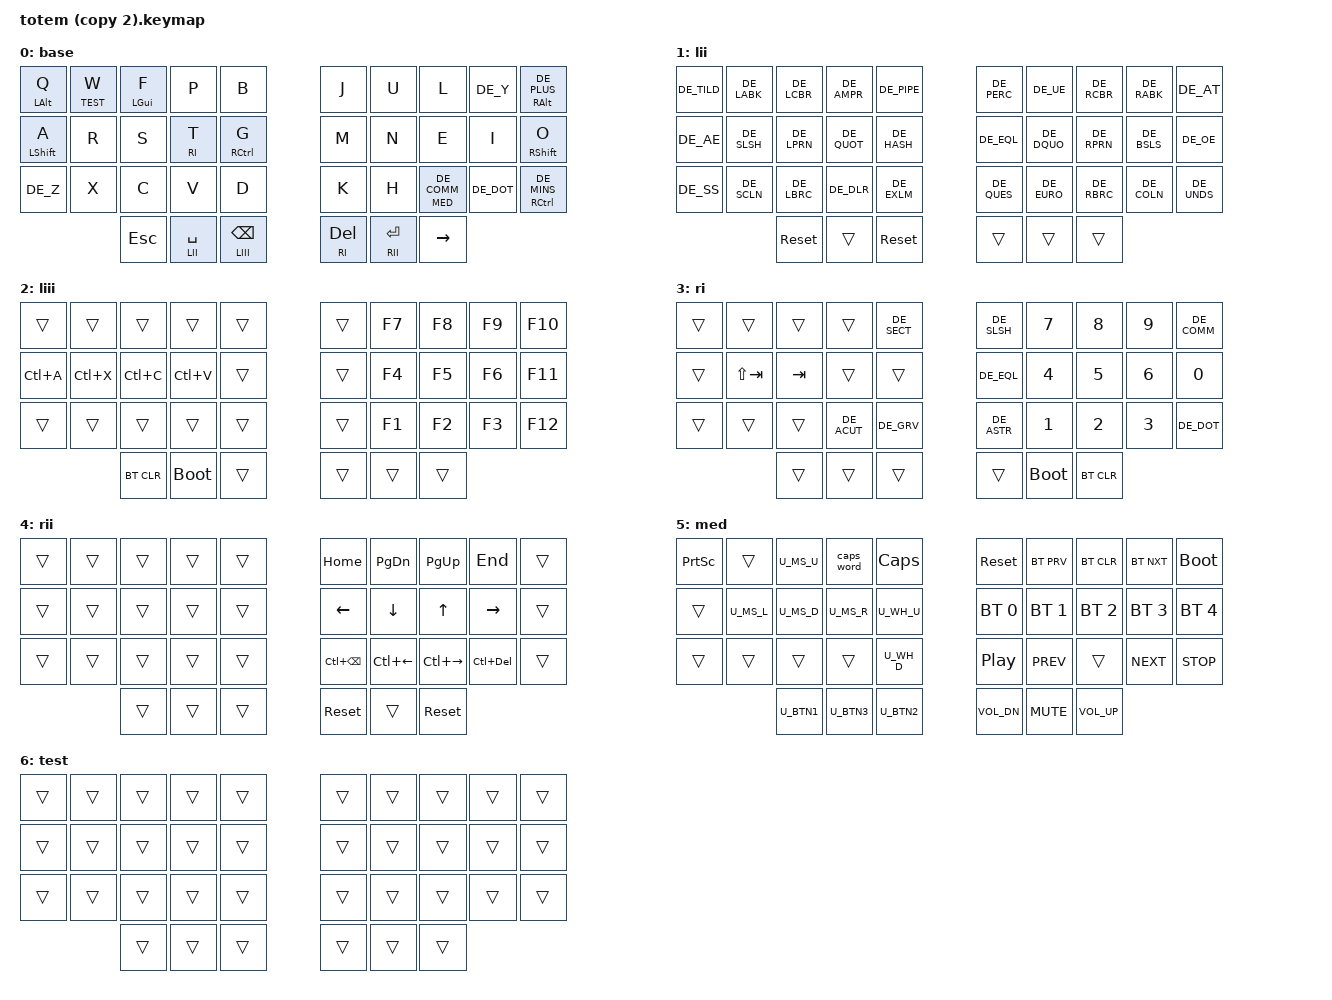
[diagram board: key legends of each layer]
// g f austauschen ... a nachlöten, switch ooooooAAZZAAQQoooAAAISEoooIsFLHAHVE
#include <behaviors.dtsi>
#include <dt-bindings/zmk/keys.h>
#include <dt-bindings/zmk/bt.h>
#include <dt-bindings/zmk/outputs.h>
#include "helper.h"
#define HOST_OS 1
#include "german-keymap.h"
#include "mouse.dtsi"

#define XXX &none
#define ___ &trans

#define BASE 0
#define LII  1
#define LIII 2
#define RI   3
#define RII  4
#define MED  5
#define TEST 6

&mt {
  quick-tap-ms = <175>;
  global-quick-tap;
  flavor = "balanced";
  tapping-term-ms = <200>;
};

// CONFIG_ZMK_SLEEP=y
// CONFIG_ZMK_IDLE_TIMEOUT=1800000
// CONFIG_ZMK_IDLE_SLEEP_TIMEOUT=3600000


 // ZMK_BEHAVIOR(ssd, hold_tap,
 //     flavor = "balanced";
 //     tapping-term-ms = <280>;
 //     quick-tap-ms = <125>;
 //     bindings = <&kp>, <&kp>;
 // )
 // ZMK_BEHAVIOR(a_u, macro,
 //     bindings = <&macro_tap &kp O>;
 // )


/ {
    macros {
        s1: s1 {
            label = "s1";
            compatible = "zmk,behavior-macro-one-param";
            #binding-cells = <1>;
            bindings
                = <&macro_tap &kp Z>,
                  <&macro_param_1to1>,
                  <&kp MACRO_PLACEHOLDER>
                  ;
        };
    };
};



//  ┏━━━━━━━━━━━━━━━━━━━━━━━┓
       ZMK_LAYER(base,
//  ┗━━━━━━━━━━━┳━━━━━━━━━━━╋━━━━━━━━━━━━━━━━━━━━━━━┳━━━━━━━━━━━┓   ┏━━━━━━━━━━━┳━━━━━━━━━━━┳━━━━━━━━━━━┳━━━━━━━━━━━┳━━━━━━━━━━━┓
//  ┃   A_Q     ┃     W     ┃    M_F    ┃     P     ┃     B     ┃   ┃     J     ┃     U     ┃     L     ┃       Y   ┃   A_+     ┃
    &mt LALT Q   &lt TEST W  &mt LGUI F   &kp P       &kp B           &kp J       &kp U       &kp L      &kp DE_Y    &mt RALT DE_PLUS
//  ┣━━━━━━━━━━━╋━━━━━━━━━━━╋━━━━━━━━━━━╋━━━━━━━━━━━╋━━━━━━━━━━━┫   ┣━━━━━━━━━━━╋━━━━━━━━━━━╋━━━━━━━━━━━╋━━━━━━━━━━━╋━━━━━━━━━━━┫
//  ┃   S_A     ┃     R     ┃     S     ┃     T     ┃   C_G     ┃   ┃     M     ┃     N     ┃     E     ┃     I     ┃   S_O     ┃
    &mt LSHIFT A  &kp R       &kp S       &lt RI T   &mt RCTRL G      &kp M       &kp N       &kp E       &kp I       &mt RSHIFT O      
//  ┣━━━━━━━━━━━╋━━━━━━━━━━━╋━━━━━━━━━━━╋━━━━━━━━━━━╋━━━━━━━━━━━┫   ┣━━━━━━━━━━━╋━━━━━━━━━━━╋━━━━━━━━━━━╋━━━━━━━━━━━╋━━━━━━━━━━━┫
//  ┃     Z     ┃     X     ┃     C     ┃     V     ┃     D     ┃   ┃     K     ┃     H     ┃     ,     ┃     .     ┃   C_-     ┃
     &kp DE_Z     &kp X       &kp C       &kp V       &kp D           &kp K      &kp H &lt MED DE_COMM    &kp DE_DOT &mt RCTRL DE_MINS
//  ┗━━━━━━━━━━━┻━━━━━━━━━━━╋━━━━━━━━━━━╋━━━━━━━━━━━╋━━━━━━━━━━━┫   ┣━━━━━━━━━━━╋━━━━━━━━━━━╋━━━━━━━━━━━╋━━━━━━━━━━━┻━━━━━━━━━━━┛
//                          ┃   ESC     ┃     SPACE ┃     BSPC  ┃   ┃ DELETE    ┃  RETURN   ┃  RGHT     ┃
                            &kp ESC     &lt LII SPACE &lt LIII BSPC &lt RI DEL   &lt RII RET  &kp RIGHT    
)//                         ┗━━━━━━━━━━━┻━━━━━━━━━━━┻━━━━━━━━━━━┛   ┗━━━━━━━━━━━┻━━━━━━━━━━━┻━━━━━━━━━━━┛

//  ┏━━━━━━━━━━━━━━━━━━━━━━━┓
       ZMK_LAYER(lii,
//  ┗━━━━━━━━━━━╋━━━━━━━━━━━╋━━━━━━━━━━━━━━━━━━━━━━━┳━━━━━━━━━━━┓   ┏━━━━━━━━━━━┳━━━━━━━━━━━┳━━━━━━━━━━━┳━━━━━━━━━━━┳━━━━━━━━━━━┓
//  ┃     ~     ┃     <     ┃     {     ┃    &      ┃     |     ┃   ┃     %     ┃     ü     ┃     }     ┃     >     ┃     @     ┃
     &kp DE_TILD &kp DE_LABK &kp DE_LCBR &kp DE_AMPR &kp DE_PIPE     &kp DE_PERC   &kp DE_UE   &kp DE_RCBR  &kp DE_RABK &kp DE_AT
//  ┣━━━━━━━━━━━╋━━━━━━━━━━━╋━━━━━━━━━━━╋━━━━━━━━━━━╋━━━━━━━━━━━┫   ┣━━━━━━━━━━━╋━━━━━━━━━━━╋━━━━━━━━━━━╋━━━━━━━━━━━╋━━━━━━━━━━━┫
//  ┃   ä       ┃     SLSH  ┃    (      ┃   '       ┃    HASH   ┃   ┃     =     ┃     "     ┃     )     ┃   BSLS    ┃     ö     ┃
     &kp DE_AE   &kp DE_SLSH &kp DE_LPRN &kp DE_QUOT &kp DE_HASH      &kp DE_EQL &kp DE_DQUO &kp DE_RPRN &kp DE_BSLS  &kp DE_OE
//  ┣━━━━━━━━━━━╋━━━━━━━━━━━╋━━━━━━━━━━━╋━━━━━━━━━━━╋━━━━━━━━━━━┫   ┣━━━━━━━━━━━╋━━━━━━━━━━━╋━━━━━━━━━━━╋━━━━━━━━━━━╋━━━━━━━━━━━┫
//  ┃     ß     ┃    ;      ┃    [      ┃    $      ┃     !     ┃   ┃     ?     ┃     €     ┃     ]     ┃     :     ┃     _     ┃
     &kp DE_SS    &kp DE_SCLN &kp DE_LBRC &kp DE_DLR  &kp DE_EXLM    &kp DE_QUES  &kp DE_EURO &kp DE_RBRC &kp DE_COLN &kp DE_UNDS   
//  ┗━━━━━━━━━━━┻━━━━━━━━━━━╋━━━━━━━━━━━╋━━━━━━━━━━━╋━━━━━━━━━━━┫   ┣━━━━━━━━━━━╋━━━━━━━━━━━╋━━━━━━━━━━━╋━━━━━━━━━━━┻━━━━━━━━━━━┛
//                          ┃   RESET   ┃    ###    ┃  RESET    ┃   ┃           ┃           ┃           ┃
                             &sys_reset      ___      &sys_reset         ___         ___         ___
)//                         ┗━━━━━━━━━━━┻━━━━━━━━━━━┻━━━━━━━━━━━┛   ┗━━━━━━━━━━━┻━━━━━━━━━━━┻━━━━━━━━━━━┛

//  ┏━━━━━━━━━━━━━━━━━━━━━━━┓
       ZMK_LAYER(liii,
//  ┗━━━━━━━━━━━╋━━━━━━━━━━━╋━━━━━━━━━━━━━━━━━━━━━━━┳━━━━━━━━━━━┓   ┏━━━━━━━━━━━┳━━━━━━━━━━━┳━━━━━━━━━━━┳━━━━━━━━━━━┳━━━━━━━━━━━┓
//  ┃           ┃           ┃           ┃           ┃           ┃   ┃           ┃    F7     ┃    F8     ┃    F9     ┃    F10    ┃
         ___         ___         ___         ___         ___             ___     &kp F7      &kp F8      &kp F9      &kp F10
//  ┣━━━━━━━━━━━╋━━━━━━━━━━━╋━━━━━━━━━━━╋━━━━━━━━━━━╋━━━━━━━━━━━┫   ┣━━━━━━━━━━━╋━━━━━━━━━━━╋━━━━━━━━━━━╋━━━━━━━━━━━╋━━━━━━━━━━━┫
//  ┃   C-A     ┃   C-X     ┃   C-C     ┃    C-V    ┃           ┃   ┃           ┃    F4     ┃    F5     ┃    F6     ┃    F11    ┃
      &kp LC(A)   &kp LC(X)   &kp LC(C)   &kp LC(V)      ___             ___     &kp F4      &kp F5      &kp F6      &kp F11  
//  ┣━━━━━━━━━━━╋━━━━━━━━━━━╋━━━━━━━━━━━╋━━━━━━━━━━━╋━━━━━━━━━━━┫   ┣━━━━━━━━━━━╋━━━━━━━━━━━╋━━━━━━━━━━━╋━━━━━━━━━━━╋━━━━━━━━━━━┫
//  ┃           ┃           ┃           ┃           ┃           ┃   ┃           ┃    F1     ┃    F2     ┃    F3     ┃    F12    ┃
         ___          ___         ___        ___         ___             ___     &kp F1      &kp F2      &kp F3      &kp F12           
//  ┗━━━━━━━━━━━┻━━━━━━━━━━━╋━━━━━━━━━━━╋━━━━━━━━━━━╋━━━━━━━━━━━┫   ┣━━━━━━━━━━━╋━━━━━━━━━━━╋━━━━━━━━━━━╋━━━━━━━━━━━┻━━━━━━━━━━━┛
//                          ┃           ┃           ┃     ---   ┃   ┃           ┃           ┃           ┃
                             &bt BT_CLR  &bootloader      ___             ___          ___      ___     
)//                         ┗━━━━━━━━━━━┻━━━━━━━━━━━┻━━━━━━━━━━━┛   ┗━━━━━━━━━━━┻━━━━━━━━━━━┻━━━━━━━━━━━┛

//  ┏━━━━━━━━━━━━━━━━━━━━━━━┓
       ZMK_LAYER(ri,
//  ┗━━━━━━━━━━━╋━━━━━━━━━━━╋━━━━━━━━━━━━━━━━━━━━━━━┳━━━━━━━━━━━┓   ┏━━━━━━━━━━━┳━━━━━━━━━━━┳━━━━━━━━━━━┳━━━━━━━━━━━┳━━━━━━━━━━━┓
//  ┃           ┃           ┃           ┃           ┃     §     ┃   ┃     /     ┃     7     ┃     8     ┃     9     ┃     ,     ┃
         ___          ___         ___        ___     &kp DE_SECT     &kp DE_SLSH   &kp N7      &kp N8      &kp N9      &kp DE_COMM 
//  ┣━━━━━━━━━━━╋━━━━━━━━━━━╋━━━━━━━━━━━╋━━━━━━━━━━━╋━━━━━━━━━━━┫   ┣━━━━━━━━━━━╋━━━━━━━━━━━╋━━━━━━━━━━━╋━━━━━━━━━━━╋━━━━━━━━━━━┫
//  ┃           ┃           ┃           ┃    XXX    ┃           ┃   ┃     =     ┃     4     ┃     5     ┃     6     ┃     0     ┃
         ___     &kp LS(TAB) &kp TAB     ___         ___          &kp DE_EQL &kp N4      &kp N5      &kp N6      &kp N0
//  ┣━━━━━━━━━━━╋━━━━━━━━━━━╋━━━━━━━━━━━╋━━━━━━━━━━━╋━━━━━━━━━━━┫   ┣━━━━━━━━━━━╋━━━━━━━━━━━╋━━━━━━━━━━━╋━━━━━━━━━━━╋━━━━━━━━━━━┫
//  ┃           ┃           ┃           ┃     ´     ┃     `     ┃   ┃     *     ┃     1     ┃     2     ┃     3     ┃     .     ┃
         ___          ___         ___    &kp DE_ACUT  &kp DE_GRV     &kp DE_ASTR &kp N1      &kp N2      &kp N3       &kp DE_DOT
//  ┗━━━━━━━━━━━┻━━━━━━━━━━━╋━━━━━━━━━━━╋━━━━━━━━━━━╋━━━━━━━━━━━┫   ┣━━━━━━━━━━━╋━━━━━━━━━━━╋━━━━━━━━━━━╋━━━━━━━━━━━┻━━━━━━━━━━━┛
//                          ┃           ┃           ┃           ┃   ┃    ---    ┃           ┃           ┃
                                 ___         ___         ___             ___      &bootloader &bt BT_CLR
)//                         ┗━━━━━━━━━━━┻━━━━━━━━━━━┻━━━━━━━━━━━┛   ┗━━━━━━━━━━━┻━━━━━━━━━━━┻━━━━━━━━━━━┛

//  ┏━━━━━━━━━━━━━━━━━━━━━━━┓
       ZMK_LAYER(rii, 
//  ┗━━━━━━━━━━━╋━━━━━━━━━━━╋━━━━━━━━━━━━━━━━━━━━━━━┳━━━━━━━━━━━┓   ┏━━━━━━━━━━━┳━━━━━━━━━━━┳━━━━━━━━━━━┳━━━━━━━━━━━┳━━━━━━━━━━━┓
//  ┃           ┃           ┃           ┃           ┃           ┃   ┃   HOME    ┃    PGDN   ┃   PGUP    ┃  END      ┃           ┃
         ___          ___         ___        ___         ___          &kp HOME     &kp PG_DN   &kp PG_UP  &kp END         ___     
//  ┣━━━━━━━━━━━╋━━━━━━━━━━━╋━━━━━━━━━━━╋━━━━━━━━━━━╋━━━━━━━━━━━┫   ┣━━━━━━━━━━━╋━━━━━━━━━━━╋━━━━━━━━━━━╋━━━━━━━━━━━╋━━━━━━━━━━━┫
//  ┃           ┃           ┃           ┃           ┃           ┃   ┃   LEFT    ┃    DOWN   ┃    UP     ┃    RIGHT  ┃           ┃
         ___          ___         ___        ___         ___            &kp LEFT     &kp DOWN    &kp UP     &kp RIGHT     ___    
//  ┣━━━━━━━━━━━╋━━━━━━━━━━━╋━━━━━━━━━━━╋━━━━━━━━━━━╋━━━━━━━━━━━┫   ┣━━━━━━━━━━━╋━━━━━━━━━━━╋━━━━━━━━━━━╋━━━━━━━━━━━╋━━━━━━━━━━━┫
//  ┃           ┃           ┃           ┃           ┃           ┃   ┃  C-BSPC   ┃ C-LEFT    ┃ C_RGHT    ┃  C_DEL    ┃  DLINE    ┃
         ___          ___         ___        ___         ___       &kp LC(BSPC) &kp LC(LEFT) &kp LC(RIGHT) &kp LC(DEL)   ___ 
//  ┗━━━━━━━━━━━┻━━━━━━━━━━━╋━━━━━━━━━━━╋━━━━━━━━━━━╋━━━━━━━━━━━┫   ┣━━━━━━━━━━━╋━━━━━━━━━━━╋━━━━━━━━━━━╋━━━━━━━━━━━┻━━━━━━━━━━━┛
//                          ┃           ┃           ┃           ┃   ┃           ┃    XXX    ┃           ┃
                                 ___         ___         ___         &sys_reset      ___      &sys_reset
)//                         ┗━━━━━━━━━━━┻━━━━━━━━━━━┻━━━━━━━━━━━┛   ┗━━━━━━━━━━━┻━━━━━━━━━━━┻━━━━━━━━━━━┛

//  ┏━━━━━━━━━━━━━━━━━━━━━━━┓
       ZMK_LAYER( med,
//  ┗━━━━━━━━━━━╋━━━━━━━━━━━╋━━━━━━━━━━━━━━━━━━━━━━━┳━━━━━━━━━━━┓   ┏━━━━━━━━━━━┳━━━━━━━━━━━┳━━━━━━━━━━━┳━━━━━━━━━━━┳━━━━━━━━━━━┓
//  ┃  PRN SCRN ┃           ┃   M UP    ┃           ┃   CAPS    ┃   ┃   RESET   ┃   BT PRV  ┃ BT CLEAR  ┃  BT NXT   ┃BOOTLOADER ┃
       &kp PSCRN     ___      U_MS_U      &caps_word   &kp CAPS       &sys_reset  &bt BT_PRV  &bt BT_CLR  &bt BT_NXT &bootloader
//  ┣━━━━━━━━━━━╋━━━━━━━━━━━╋━━━━━━━━━━━╋━━━━━━━━━━━╋━━━━━━━━━━━┫   ┣━━━━━━━━━━━╋━━━━━━━━━━━╋━━━━━━━━━━━╋━━━━━━━━━━━╋━━━━━━━━━━━┫
//  ┃           ┃  M RIGHT  ┃   M DOWN  ┃  M RIGHT  ┃ Scroll U  ┃   ┃    B1     ┃    B2     ┃    B3     ┃    B4     ┃    B5     ┃
         ___       U_MS_L     U_MS_D       U_MS_R      U_WH_U      &bt BT_SEL 0 &bt BT_SEL 1 &bt BT_SEL 2 &bt BT_SEL 3 &bt BT_SEL 4 
//  ┣━━━━━━━━━━━╋━━━━━━━━━━━╋━━━━━━━━━━━╋━━━━━━━━━━━╋━━━━━━━━━━━┫   ┣━━━━━━━━━━━╋━━━━━━━━━━━╋━━━━━━━━━━━╋━━━━━━━━━━━╋━━━━━━━━━━━┫
//  ┃           ┃           ┃           ┃           ┃  Scroll D ┃   ┃ PLAY PAUSE┃  PREV     ┃    XXX    ┃  NEXT     ┃   STOP    ┃
         ___         ___         ___         ___        U_WH_D        &kp C_PP   &kp C_PREV      ___      &kp C_NEXT  &kp C_STOP
//  ┗━━━━━━━━━━━┻━━━━━━━━━━━╋━━━━━━━━━━━╋━━━━━━━━━━━╋━━━━━━━━━━━┫   ┣━━━━━━━━━━━┻━━━━━━━━━━━╋━━━━━━━━━━━╋━━━━━━━━━━━╋━━━━━━━━━━━┛
//                          ┃  MS Lft   ┃  MS Mid   ┃  MS Rght  ┃   ┃ VOL DOWN  ┃   MUTE    ┃  VOL UP   ┃
                               U_BTN1      U_BTN3      U_BTN2       &kp C_VOL_DN  &kp C_MUTE &kp C_VOL_UP
)//                         ┗━━━━━━━━━━━┻━━━━━━━━━━━┻━━━━━━━━━━━┛   ┗━━━━━━━━━━━┻━━━━━━━━━━━┻━━━━━━━━━━━┛


//  ┏━━━━━━━━━━━━━━━━━━━━━━━┓
       ZMK_LAYER( test,
//  ┗━━━━━━━━━━━╋━━━━━━━━━━━╋━━━━━━━━━━━━━━━━━━━━━━━┳━━━━━━━━━━━┓   ┏━━━━━━━━━━━┳━━━━━━━━━━━┳━━━━━━━━━━━┳━━━━━━━━━━━┳━━━━━━━━━━━┓
//  ┃           ┃    XXX    ┃           ┃           ┃           ┃   ┃           ┃           ┃           ┃           ┃           ┃
          ___         ___         ___        ___         ___            ___         ___         ___        ___         ___
//  ┣━━━━━━━━━━━╋━━━━━━━━━━━╋━━━━━━━━━━━╋━━━━━━━━━━━╋━━━━━━━━━━━┫   ┣━━━━━━━━━━━╋━━━━━━━━━━━╋━━━━━━━━━━━╋━━━━━━━━━━━╋━━━━━━━━━━━┫
//  ┃           ┃           ┃           ┃           ┃           ┃   ┃           ┃           ┃           ┃           ┃           ┃ 
         ___         ___         ___         ___         ___             ___         ___         ___        ___         ___
//  ┣━━━━━━━━━━━╋━━━━━━━━━━━╋━━━━━━━━━━━╋━━━━━━━━━━━╋━━━━━━━━━━━┫   ┣━━━━━━━━━━━╋━━━━━━━━━━━╋━━━━━━━━━━━╋━━━━━━━━━━━╋━━━━━━━━━━━┫
//  ┃           ┃           ┃           ┃           ┃           ┃   ┃           ┃           ┃           ┃           ┃           ┃ 
         ___         ___         ___         ___         ___             ___         ___         ___        ___         ___
//  ┗━━━━━━━━━━━┻━━━━━━━━━━━╋━━━━━━━━━━━╋━━━━━━━━━━━╋━━━━━━━━━━━┫   ┣━━━━━━━━━━━╋━━━━━━━━━━━╋━━━━━━━━━━━╋━━━━━━━━━━━┻━━━━━━━━━━━┛
//                          ┃           ┃           ┃           ┃   ┃           ┃    ---    ┃           ┃
                                ___          ___         ___             ___         ___        ___
)//                         ┗━━━━━━━━━━━┻━━━━━━━━━━━┻━━━━━━━━━━━┛   ┗━━━━━━━━━━━┻━━━━━━━━━━━┻━━━━━━━━━━━┛
